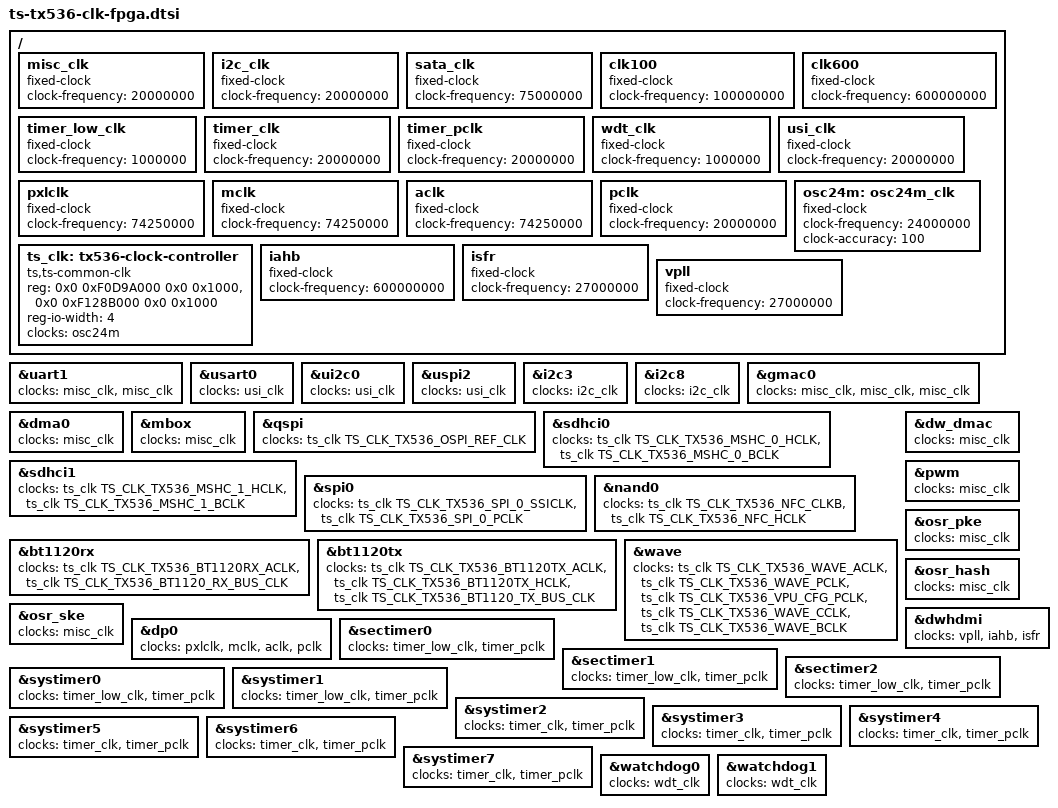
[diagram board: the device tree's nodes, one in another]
/*
 * dts file for tsingmicro tx536
 *
 * Copyright 2022 Tsingmicro, Inc.
 *
 * This program is free software; you can redistribute it and/or
 * modify it under the terms of the GNU General Public License as
 * published by the Free Software Foundation; either version 2 of
 * the License, or (at your option) any later version.
 */


#include <dt-bindings/clock/ts-tx536-clk.h>
/ {
	misc_clk: misc_clk {
		compatible = "fixed-clock";
		#clock-cells = <0>;
		clock-frequency = <20000000>;
	};

	i2c_clk: i2c_clk {
		compatible = "fixed-clock";
		#clock-cells = <0x0>;
		clock-frequency = <20000000>;
	};

	sata_clk: sata_clk {
		compatible = "fixed-clock";
		#clock-cells = <0>;
		clock-frequency = <75000000>;
	};

	clk100: clk100 {
		compatible = "fixed-clock";
		#clock-cells = <0>;
		clock-frequency = <100000000>;
	};

	clk600: clk600 {
		compatible = "fixed-clock";
		#clock-cells = <0>;
		clock-frequency = <600000000>;
	};

	timer_low_clk: timer_low_clk {
		compatible = "fixed-clock";
		#clock-cells = <0x0>;
		clock-frequency = <1000000>;
	};

	timer_clk: timer_clk {
		compatible = "fixed-clock";
		#clock-cells = <0x0>;
		clock-frequency = <20000000>;
	};

	timer_pclk: timer_pclk {
		compatible = "fixed-clock";
		#clock-cells = <0x0>;
		clock-frequency = <20000000>;
	};

	wdt_clk: wdt_clk {
		compatible = "fixed-clock";
		#clock-cells = <0x0>;
		clock-frequency = <1000000>;
	};

	usi_clk: usi_clk {
		compatible = "fixed-clock";
		#clock-cells = <0x0>;
		clock-frequency = <20000000>;
	};
	pxlclk: pxlclk {
		compatible = "fixed-clock";
		#clock-cells = <0>;
		clock-frequency = <74250000>;
	};

	mclk: mclk {
		compatible = "fixed-clock";
		#clock-cells = <0>;
		clock-frequency = <74250000>;
	};

	aclk: aclk {
		compatible = "fixed-clock";
		#clock-cells = <0>;
		clock-frequency = <74250000>;
	};

	pclk: pclk {
		compatible = "fixed-clock";
		#clock-cells = <0>;
		clock-frequency = <20000000>;
	};

	osc24m: osc24m_clk {
		compatible = "fixed-clock";
		#clock-cells = <0>;
		clock-frequency = <24000000>;
		clock-accuracy = <100>;
	};

	ts_clk: tx536-clock-controller {
		compatible = "ts,ts-common-clk";
		reg = <0x0 0xF0D9A000 0x0 0x1000>,
			  <0x0 0xF128B000 0x0 0x1000>;
		reg-io-width = <4>;
		#clock-cells = <1>;
		clocks = <&osc24m>;
	};

	iahb: iahb {
		compatible = "fixed-clock";
		#clock-cells = <0>;
		clock-frequency = <600000000>;//600M
	};

	isfr: isfr {
		compatible = "fixed-clock";
		#clock-cells = <0>;
		clock-frequency = <27000000>;//27M
	};

	vpll: vpll {
		compatible = "fixed-clock";
		#clock-cells = <0>;
		clock-frequency = <27000000>;//27M
	};

};

&uart1 {
	clocks = <&misc_clk &misc_clk>;
	clock-names = "uart_clk", "pclk";
};

&usart0 {
	clocks = <&usi_clk>;
	clock-names = "usi_clk";
};

&ui2c0 {
	clocks = <&usi_clk>;
	clock-names = "usi_clk";
};

&uspi2 {
	clocks = <&usi_clk>;
	clock-names = "usi_clk";
};

&i2c3 {
	clocks = <&i2c_clk>;
};

&i2c8 {
	clocks = <&i2c_clk>;
};

&gmac0 {
	clocks = <&misc_clk>, <&misc_clk>, <&misc_clk>;
};

&dma0 {
	clocks = <&misc_clk>;
	clock-names = "apb_pclk";
};

&mbox {
	clocks = <&misc_clk>;
};

#if 0
&can0 {
	clocks = <&misc_clk &misc_clk>;
};

&can1 {
	clocks = <&misc_clk &misc_clk>;
};

&gpio {
	clocks = <&misc_clk>;
};

&sata {
	clocks = <&sata_clk>;
};

&sdhci0 {
	clocks = <&misc_clk>, <&misc_clk>;
};

&sdhci1 {
	clocks = <&misc_clk>, <&misc_clk>;
};

&spi0 {
	clocks = <&misc_clk &misc_clk>;
};

&spi1 {
	clocks = <&misc_clk &misc_clk>;
};

&usb0 {
	clocks = <&misc_clk>, <&misc_clk>;
};

&usb1 {
	clocks = <&misc_clk>, <&misc_clk>;
};

&watchdog0 {
	clocks= <&misc_clk>;
};
#endif

&qspi {
	clocks = <&ts_clk TS_CLK_TX536_OSPI_REF_CLK>;
	clock-names = "ospi_refclk";
};

&sdhci0 {
	clocks = <&ts_clk TS_CLK_TX536_MSHC_0_HCLK>, <&ts_clk TS_CLK_TX536_MSHC_0_BCLK>;
	clock-names = "core", "bus";
};

&sdhci1 {
	clocks = <&ts_clk TS_CLK_TX536_MSHC_1_HCLK>, <&ts_clk TS_CLK_TX536_MSHC_1_BCLK>;
	clock-names = "core", "bus";
};

&spi0 {
	clocks = <&ts_clk TS_CLK_TX536_SPI_0_SSICLK>, <&ts_clk TS_CLK_TX536_SPI_0_PCLK>;
	clock-names = "ref_clk", "pclk";
};

&nand0 {
	clocks = <&ts_clk TS_CLK_TX536_NFC_CLKB>, <&ts_clk TS_CLK_TX536_NFC_HCLK>;
	clock-names = "nfc_clkb, nfc_hclk";
};

&bt1120rx {
	clocks = <&ts_clk TS_CLK_TX536_BT1120RX_ACLK>,
		<&ts_clk TS_CLK_TX536_BT1120_RX_BUS_CLK>;
	clock-names = "bt1120rx_aclk", "bt1120_rx_bus_clk";
};

&bt1120tx {
	clocks = <&ts_clk TS_CLK_TX536_BT1120TX_ACLK>,
		<&ts_clk TS_CLK_TX536_BT1120TX_HCLK>,
		<&ts_clk TS_CLK_TX536_BT1120_TX_BUS_CLK>;
	clock-names = "bt1120tx_aclk", "bt1120tx_hclk", "bt1120_tx_bus_clk";
};

&wave {
	clocks = <&ts_clk TS_CLK_TX536_WAVE_ACLK>,
			<&ts_clk TS_CLK_TX536_WAVE_PCLK>,
			<&ts_clk TS_CLK_TX536_VPU_CFG_PCLK>,
			<&ts_clk TS_CLK_TX536_WAVE_CCLK>,
			<&ts_clk TS_CLK_TX536_WAVE_BCLK>;
	clock-names = "awave", "pwave","pcfgwave", "cwave","bwave";
};

&dw_dmac {
	clocks = <&misc_clk>;
};

&pwm {
	clocks = <&misc_clk>;
};

&osr_pke {
	clocks = <&misc_clk>;
};

&osr_hash {
	clocks = <&misc_clk>;
};

&osr_ske {
	clocks = <&misc_clk>;
};

&dp0 {
	clocks = <&pxlclk>, <&mclk>, <&aclk>, <&pclk>;
	clock-names = "pxlclk", "mclk", "aclk", "pclk";
};

&dwhdmi {
	clocks = <&vpll>, <&iahb>, <&isfr>;
	clock-names = "vpll", "iahb", "isfr";
};

&sectimer0 {
	clocks = <&timer_low_clk>, <&timer_pclk>;
	clock-names = "timer", "pclk";
};

&sectimer1 {
	clocks = <&timer_low_clk>, <&timer_pclk>;
	clock-names = "timer", "pclk";
};

&sectimer2 {
	clocks = <&timer_low_clk>, <&timer_pclk>;
	clock-names = "timer", "pclk";
};

&systimer0 {
	clocks = <&timer_low_clk>, <&timer_pclk>;
	clock-names = "timer", "pclk";
};

&systimer1 {
	clocks = <&timer_low_clk>, <&timer_pclk>;
	clock-names = "timer", "pclk";
};

&systimer2 {
	clocks = <&timer_clk>, <&timer_pclk>;
	clock-names = "timer", "pclk";
};

&systimer3 {
	clocks = <&timer_clk>, <&timer_pclk>;
	clock-names = "timer", "pclk";
};

&systimer4 {
	clocks = <&timer_clk>, <&timer_pclk>;
	clock-names = "timer", "pclk";
};

&systimer5 {
	clocks = <&timer_clk>, <&timer_pclk>;
	clock-names = "timer", "pclk";
};

&systimer6 {
	clocks = <&timer_clk>, <&timer_pclk>;
	clock-names = "timer", "pclk";
};

&systimer7 {
	clocks = <&timer_clk>, <&timer_pclk>;
	clock-names = "timer", "pclk";
};

&watchdog0 {
	clocks = <&wdt_clk>;
};

&watchdog1 {
	clocks = <&wdt_clk>;
};

